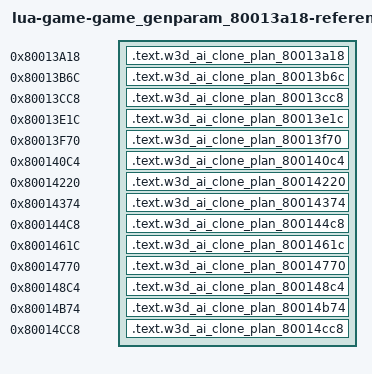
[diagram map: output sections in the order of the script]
/* Generated reference-only placements. All bodies are source-built. */
OUTPUT_FORMAT("elf32-powerpc")
OUTPUT_ARCH(powerpc)
ENTRY(w3d_ai_clone_plan_80013a18)
_SDA_BASE_ = 0x804b2540;
_SDA2_BASE_ = 0x804c2540;
w3d_f32_8036a4e0 = 0x8036a4e0;
w3d_f32_8036a4e4 = 0x8036a4e4;
w3d_f32_8036a4ec = 0x8036a4ec;
w3d_f32_8036a4f0 = 0x8036a4f0;
w3d_f32_8036a4f4 = 0x8036a4f4;
w3d_f32_8036a4f8 = 0x8036a4f8;
w3d_f32_8036a500 = 0x8036a500;
w3d_f32_8036a504 = 0x8036a504;
w3d_f32_8036a50c = 0x8036a50c;
w3d_f32_8036a510 = 0x8036a510;
w3d_f32_8036a514 = 0x8036a514;
w3d_f32_8036a518 = 0x8036a518;
w3d_f32_8036a524 = 0x8036a524;
w3d_f32_8036a528 = 0x8036a528;
w3d_path_cost_construct = 0x80006360;
w3d_vtable_8040cd58 = 0x8040cd58;
w3d_vtable_8040cd90 = 0x8040cd90;
w3d_vtable_8040ce38 = 0x8040ce38;
w3d_vtable_8040ce70 = 0x8040ce70;
w3d_vtable_8040cea8 = 0x8040cea8;
w3d_vtable_8040cee0 = 0x8040cee0;
w3d_vtable_8040cf50 = 0x8040cf50;
w3d_vtable_8040cf88 = 0x8040cf88;
w3d_vtable_8040cff8 = 0x8040cff8;
w3d_vtable_8040d030 = 0x8040d030;
w3d_vtable_8040d068 = 0x8040d068;
w3d_vtable_8040d0a0 = 0x8040d0a0;
w3d_vtable_8040d110 = 0x8040d110;
w3d_vtable_8040d148 = 0x8040d148;
w3d_vtable_8040d7b8 = 0x8040d7b8;
SECTIONS {
  .text.w3d_ai_clone_plan_80013a18 0x80013a18 : { *(.text.w3d_ai_clone_plan_80013a18) }
  .text.w3d_ai_clone_plan_80013b6c 0x80013b6c : { *(.text.w3d_ai_clone_plan_80013b6c) }
  .text.w3d_ai_clone_plan_80013cc8 0x80013cc8 : { *(.text.w3d_ai_clone_plan_80013cc8) }
  .text.w3d_ai_clone_plan_80013e1c 0x80013e1c : { *(.text.w3d_ai_clone_plan_80013e1c) }
  .text.w3d_ai_clone_plan_80013f70 0x80013f70 : { *(.text.w3d_ai_clone_plan_80013f70) }
  .text.w3d_ai_clone_plan_800140c4 0x800140c4 : { *(.text.w3d_ai_clone_plan_800140c4) }
  .text.w3d_ai_clone_plan_80014220 0x80014220 : { *(.text.w3d_ai_clone_plan_80014220) }
  .text.w3d_ai_clone_plan_80014374 0x80014374 : { *(.text.w3d_ai_clone_plan_80014374) }
  .text.w3d_ai_clone_plan_800144c8 0x800144c8 : { *(.text.w3d_ai_clone_plan_800144c8) }
  .text.w3d_ai_clone_plan_8001461c 0x8001461c : { *(.text.w3d_ai_clone_plan_8001461c) }
  .text.w3d_ai_clone_plan_80014770 0x80014770 : { *(.text.w3d_ai_clone_plan_80014770) }
  .text.w3d_ai_clone_plan_800148c4 0x800148c4 : { *(.text.w3d_ai_clone_plan_800148c4) }
  .text.w3d_ai_clone_plan_80014b74 0x80014b74 : { *(.text.w3d_ai_clone_plan_80014b74) }
  .text.w3d_ai_clone_plan_80014cc8 0x80014cc8 : { *(.text.w3d_ai_clone_plan_80014cc8) }
  /DISCARD/ : { *(.text*) *(.rodata*) *(.data*) *(.bss*) *(.sdata*) *(.sbss*) *(.comment) }
}
